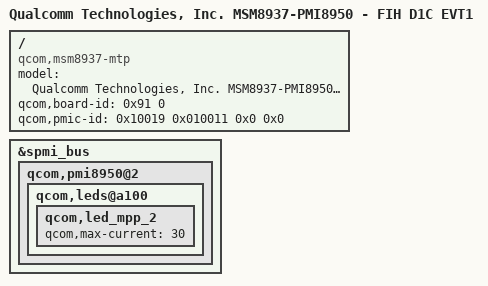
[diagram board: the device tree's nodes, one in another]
/*
 * Copyright (c) 2015-2016, The Linux Foundation. All rights reserved.
 *
 * This program is free software; you can redistribute it and/or modify
 * it under the terms of the GNU General Public License version 2 and
 * only version 2 as published by the Free Software Foundation.
 *
 * This program is distributed in the hope that it will be useful,
 * but WITHOUT ANY WARRANTY; without even the implied warranty of
 * MERCHANTABILITY or FITNESS FOR A PARTICULAR PURPOSE.  See the
 * GNU General Public License for more details.
 */

/dts-v1/;

#include "msm8937.dtsi"
#include "msm8937-pmi8950-fih-D1C-EVT.dtsi"

/ {
	model = "Qualcomm Technologies, Inc. MSM8937-PMI8950 - FIH D1C EVT1";
	compatible = "qcom,msm8937-mtp", "qcom,msm8937", "qcom,mtp";
	qcom,board-id= <0x91 0>;
	qcom,pmic-id = <0x10019 0x010011 0x0 0x0>;
};

&spmi_bus {
	qcom,pmi8950@2 {
		qcom,leds@a100 {
			qcom,led_mpp_2 {
				qcom,max-current = <30>; // Optics suggest to enlarge as 30mA, 2016/10/12
			};
		};
	};
};
